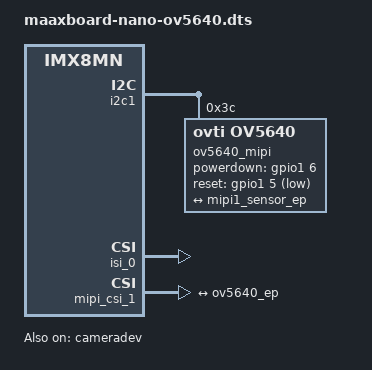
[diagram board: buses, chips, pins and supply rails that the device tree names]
/*
 * Copyright 2021 AVNET
 *
 * This program is free software; you can redistribute it and/or
 * modify it under the terms of the GNU General Public License
 * as published by the Free Software Foundation; either version 2
 * of the License, or (at your option) any later version.
 *
 * This program is distributed in the hope that it will be useful,
 * but WITHOUT ANY WARRANTY; without even the implied warranty of
 * MERCHANTABILITY or FITNESS FOR A PARTICULAR PURPOSE.  See the
 * GNU General Public License for more details.
 */

/dts-v1/;
/plugin/;

#include <dt-bindings/clock/imx8mn-clock.h>
#include <dt-bindings/gpio/gpio.h>

/ {
	compatible = "avnet,maaxboard-nano", "fsl,imx8mn";

	fragment@0 {
		target = <&i2c1>;
		__overlay__ {
			#address-cells = <1>;
			#size-cells = <0>;
			ov5640_mipi@3c {
				compatible = "ovti,ov5640";
				reg = <0x3c>;
				pinctrl-names = "default";
				pinctrl-0 = <&pinctrl_csi>;
				clocks = <&clk IMX8MN_CLK_CLKO1>;
				clock-names = "xclk";
				csi_id = <0>;
				powerdown-gpios = <&gpio1 6 GPIO_ACTIVE_HIGH>;
				reset-gpios = <&gpio1 5 GPIO_ACTIVE_LOW>;
				mclk = <24000000>;
				mclk_source = <0>;
				mipi_csi;
				status = "okay";

				port {
					ov5640_ep: endpoint {
						remote-endpoint = <&mipi1_sensor_ep>;
						data-lanes = <1 2>;
						clocks-lanes = <0>;
					};
				};
			};
		};
	};
	
	fragment@1 {
		target = <&cameradev>;
		__overlay__ {
			status = "okay";
		};
	};

	fragment@2 {
		target = <&isi_0>;
		__overlay__ {
			status = "okay";
			cap_device {
				status = "okay";
			};
		};
	};

	fragment@3 {
		target = <&mipi_csi_1>;
		__overlay__ {
			#address-cells = <1>;
			#size-cells = <0>;
			status = "okay";
			port@0 {
				reg = <0>;
				mipi1_sensor_ep: endpoint {
					remote-endpoint = <&ov5640_ep>;
					data-lanes = <2>;
					csis-hs-settle = <13>;
					csis-clk-settle = <2>;
					csis-wclk;
				};
			};
		};
	};	
};
